# RTS591x register map
Vendor: Realtek Semiconductor Corp.; Series: RTS591x Series; File version: 1.0
CPU: ARMV8MML r0p0, little endian, MPU, FPU, VTOR, 3 interrupt priority bits, 4 SAU regions
Registers are 32-bit, read-write, reset 0x0 unless marked. A register's access mark holds for its fields unless they carry their own. Offsets are from the block's base; [hi:lo] are bit positions; {n}, {i} and the like mark numbered series.

## KBM — Keyboard Matrix Controller
Base 0x40010000
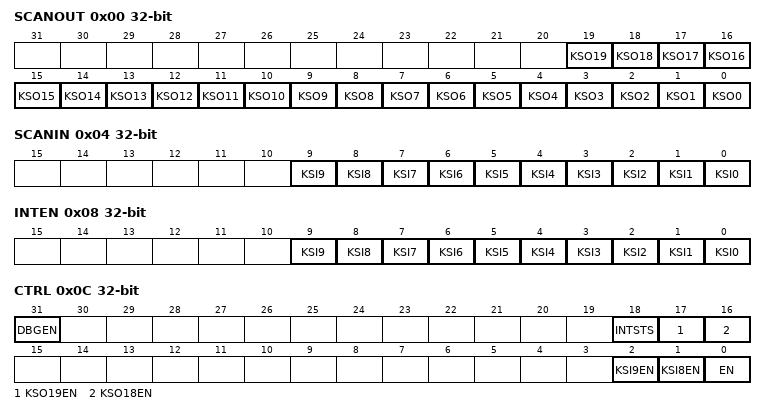
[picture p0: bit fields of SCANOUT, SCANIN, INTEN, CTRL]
0x00 SCANOUT — SCAN OUT CONTROL REGISTER
  [n] KSO{n} (n=0..19) — KSO Output Level
    0=LOW (KSO output low); 1=HIGH (KSO output high)
0x04 SCANIN ro — SACN INPUT STATUS REGISTER
  [n] KSI{n} (n=0..9) — KSI Input Level
    0=LOW (KSI input is low); 1=HIGH (KSI input is high)
0x08 INTEN — INTERRUPT ENABLE REGISTER
  [n] KSI{n} (n=0..9) — KSI Interrupt Enable
    0=DISABLE (KSI interrupt disable); 1=ENABLE (KSI interrupt enable)
0x0C CTRL — CONTROL REGISTER
  [31] DBGEN — Enable Debug Function
    0=DISABLE (Disable KBM debug function); 1=ENABLE (Enable KBM debug function)
  [18] INTSTS — Interrupt Status
    0=NOT_OCCURRED (KBM interrupt is not occurred); 1=OCCURRED (KBM interrupt is occurred)
  [17] KSO19EN — Enable KSO19
    0=DISABLE (Disable KSO19); 1=ENABLE (Enable KSO19)
  [16] KSO18EN — Enable KSO18
    0=DISABLE (Disable KSO18); 1=ENABLE (Enable KSO18)
  [2] KSI9EN — Enable KSI9
    0=DISABLE (Disable KSI9); 1=ENABLE (Enable KSI9)
  [1] KSI8EN — Enable KSI8
    0=DISABLE (Disable KSI8); 1=ENABLE (Enable KSI8)
  [0] EN — Enable KBM Controller
    0=DISABLE (Disable KBM Controller); 1=ENABLE (Enable KBM Controller)
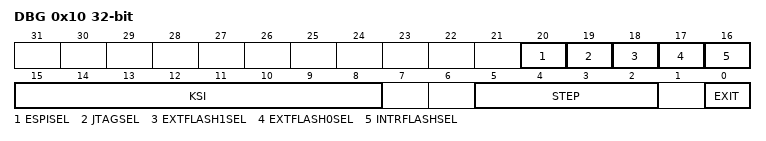
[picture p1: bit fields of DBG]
0x10 DBG ro — DEBUG REGISTER
  [20] ESPISEL — eSPI Select
  [19] JTAGSEL — JTAG Select
  [18] EXTFLASH1SEL — External Flash #1 Select
  [17] EXTFLASH0SEL — External Flash #0 Select
  [16] INTRFLASHSEL — Internal Flash Select
  [15:8] KSI — KSI Stage
  [5:2] STEP — Step Status
  [0] EXIT — Exit Mode Status

## MSPI — SPI Master Controller
Base 0x40010400
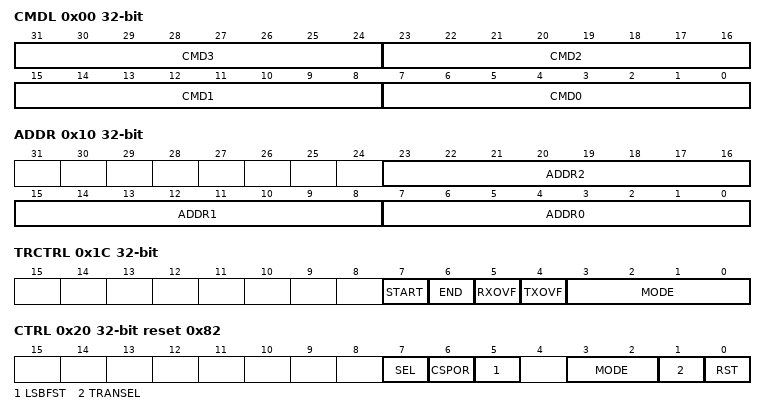
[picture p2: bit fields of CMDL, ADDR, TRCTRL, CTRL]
0x00 CMDL — COMMAND REGISTER LOW
  [8n+7:8n] CMD{n} (n=0..3) — Commmnd{n}
0x04 CMDH — COMMAND REGISTER LOW
  [7:0] CMD4 — Commmnd4
0x08 CMDNUM — COMMAND NUMBER REGISTER
  [5:0] NUM — The Bit Number Of Command To Be Transferred To SPI Device
0x10 ADDR — ADDRESS REGISTER
  [23:16] ADDR2 — Address2
  [15:8] ADDR1 — Address1
  [7:0] ADDR0 — Address0
0x14 ADDRNUM — ADDRESS NUMBER REGISTER
  [4:0] NUM — The Bit Number Of Address To Be Transferred To SPI Device
0x18 TRLEN — TRANSFER LENGTH REGISTER
  [8:0] LEN — The Length Of Data To Be Transferred
0x1C TRCTRL — TRANSFER CONTROL REGISTER
  [7] START — The Transfer Is Launch If Set This Bit
  [6] END ro — If Transfer Starts This Bit Will Be Clear Automatically By Hardware
  [5] RXOVF ro — SPI Mater Read Overflow Flag
  [4] TXOVF ro — SPI Mater Write Overflow Flag
  [3:0] MODE — Transfer Mode For Auto-mode
    0=CMD (Command mode); 1=CMDADDR (Command + address mode); 2=CMDDO (Command+Dataout mode); 3=CMDDI (Command+Datain mode); 4=CMDADDRDO (Command+Address+Dataout mode); 5=CMDADDRDI (Command+Address+Datain mode); 6=POLLSTS (Polling status); 7=FR (Fast read); 8=FRDO (Fast read with dual output); 9=FRDIO (Fast read with dual input/output)
0x20 CTRL reset 0x82 — CONTROL REGISTER
  [7] SEL — This Bit Is Used To Switch SPI And Gpio Signal
    0=GPIO (The shared pad is used as GPIO signal); 1=SPI (The shared pad is used as SPI signals)
  [6] CSPOR — This Field Indicates The Polarity Of CSLine In Idle State
    0=LOW (Low level); 1=HIGH (High level)
  [5] LSBFST — Data Transmission Order At Si And So Line
    0=MSB (MSB first); 1=LSB (LSB first)
  [3:2] MODE — SPI Mode Selection
  [1] TRANSEL — Transfer Mode Selection
    0=MANUAL (Used manual mode); 1=AUTO (Used auto-mode)
  [0] RST — Reset SPI Matser Controller
    0=DO_NOTHING; 1=RESET (Reset SPI Matser controller)
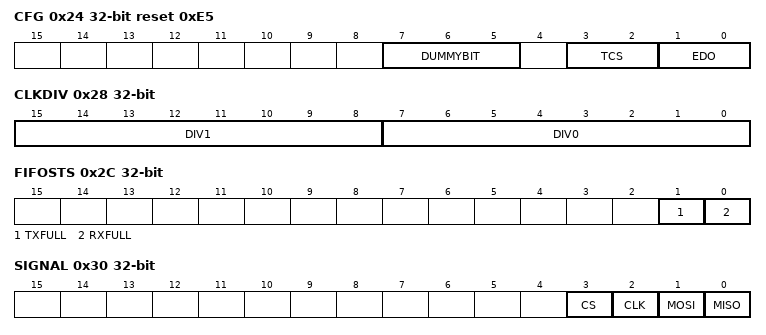
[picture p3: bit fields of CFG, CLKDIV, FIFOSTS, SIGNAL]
0x24 CFG reset 0xE5 — TIMING CONTROL REGISTER
  [7:5] DUMMYBIT — Number of dummy bit
  [3:2] TCS — Timing for CS setup and hold requirement
  [1:0] EDO — EDO timing
    0=RISING (Sample MISO at the rising edge of SCK); 1=HALF (Delay half SCK clock cycle to sample); 2=ONE (Delay one SCK clock cycle); 3=ONE_HALF (Delay one and a half SCK clock cycle)
0x28 CLKDIV — CLOCK DIVIDER REGISTER
  [15:8] DIV1 — SPI Master Clock Divider 1
  [7:0] DIV0 — SPI Master Clock Divider 0
0x2C FIFOSTS ro — FIFO STATUS REGISTER
  [1] TXFULL — SPI Master TX FIFO is full
    0=NOT_FULL (SPI Master TX FIFO is not full); 1=FULL (SPI Master TX FIFO is full)
  [0] RXFULL — SPI Master RX FIFO is Full
    0=NOT_FULL (SPI Master RX FIFO is not full); 1=FULL (SPI Master RX FIFO is full)
0x30 SIGNAL
  [3] CS
  [2] CLK — Clock
  [1] MOSI
  [0] MISO ro
0x34 TX — TX FIFO REGISTER
  [7:0] DATA — Tx data
0x38 RX ro — RX FIFO REGISTER
  [7:0] DATA — Rx data
